# MDR32F21QI register map
Vendor: Milandr; File version: 1.0
CPU: CM0 r0p0, little endian, no MPU, no FPU, 2 interrupt priority bits
Registers are 32-bit, read-write, reset 0x0 unless marked. A register's access mark holds for its fields unless they carry their own. Offsets are from the block's base; [hi:lo] are bit positions; {n}, {i} and the like mark numbered series; 'fields as' and 'values as' point back to an identical list.

## MDR_ADCUI — Energy Counter Block
Base 0x40068000
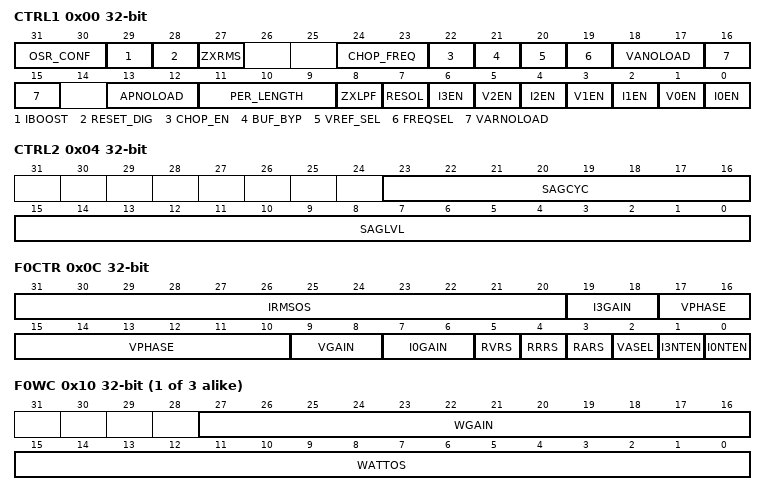
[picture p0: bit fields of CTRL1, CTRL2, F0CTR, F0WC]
0x00 CTRL1 (reset mask 0xF83FBFC3) — ADCUI Control1 Register
  [31:30] OSR_CONF — ADC Output Sampling Rate
    0=4kHz (Sampling at 4kHz); 1=8kHz (Sampling at 8kHz); 2=16kHz (Sampling at 16kHz)
  [29] IBOOST — Boost ADCUI current
  [28] RESET_DIG — Digital Logic Reset
  [27] ZXRMS — RMS Update mode
    0=Continuous RMS update; 1=OnCrossZeroV0 (Update on V0 cross zero level)
  [24:23] CHOP_FREQ — Chopper Frequency
    0=fADC_div2 (ADC freq div 2); 1=fADC_div4 (ADC freq div 4); 2=fADC_div8 (ADC freq div 8); 3=fADC_div16 (ADC freq div 16)
  [22] CHOP_EN — Chopper Mode Select
  [21] BUF_BYP — Bypass Vref buffer
  [20] VREF_SEL
    0=Internal Vref source; 1=External Vref source
  [19] FREQSEL — Enable V0 period detection to FxMD0.PER_FREQ
    0=Off (Hold Last value); 1=On (Enabled)
  [18:17] VANOLOAD — No load mode when calculating full energy
    0=All (Accumulate All Energy); 1=Ignore_Less_1p2basis (Ignore Energy less than 0.012% of full scale); 2=Ignore_Less_0p61basis (Ignore Energy less than 0.0061% of full scale); 3=Ignore_Less_0p305basis (Ignore Energy less than 0.00305% of full scale)
  [16:15] VARNOLOAD — No load mode when calculating reactive energy
    values as VANOLOAD
  [13:12] APNOLOAD — No load mode when calculating active energy
    values as VANOLOAD
  [11:9] PER_LENGTH — Period to calc aver period and dPhase
    0=Period_1 (1 period); 1=Period_2 (2 periods); 2=Period_4 (4 periods); 3=Period_8 (8 periods); 4=Period_16 (16 periods); 5=Period_32 (32 periods); 6=Period_64 (64 periods); 7=Period_128 (128 periods)
  [8] ZXLPF — V0 cross zero LPF enable
  [7] RESOL — Data resolution
    0=16 bit data; 1=24 bit data
  [2n] I{n}EN (n=0..3) — I{n} channel enable
  [5] V2EN — V2 channel enable
  [3] V1EN — V1 channel enable
  [1] V0EN — V0 channel enable
0x04 CTRL2 — ADCUI Control2 Register
  [23:16] SAGCYC — Number of voltage half periods to calc voltage drop level
  [15:0] SAGLVL — The level of permitted voltage drop
0x08 CTRL3 — ADCUI Control3 Register
  [11:0] ZTXOUT — Voltage cross zero timeout
0x0C F0CTR
  [31:20] IRMSOS — RMS calibration of channel I
  [19:18] I3GAIN — PGA value
    0=Signal amplification 0dB; 1=x2 (Signal amplification 6dB); 2=x4 (Signal amplification 12dB); 3=x8 (Signal amplification 18dB)
  [17:10] VPHASE — Phase V0 adjustment by step of +-124us
  [9:8] VGAIN — PGA value
    values as I3GAIN
  [7:6] I0GAIN — PGA value
    values as I3GAIN
  [5] RVRS wo — Full Energy Accumulator Reset
  [4] RRRS wo — Reactive Energy Accumulator Reset
  [3] RARS wo — Active Energy Accumulator Reset
  [2] VASEL — Select source for FullEnergy
    0=FullEnergy (I0DAT and VDAT can store FullEnergy); 1=I_RMS (I0DAT and VDAT can store I_RMS)
  [1] I3NTEN — I3 integrator enable
  [0] I0NTEN — I0 integrator enable
{0x10+0x58*i} F{i}WC (i=0..2) — Active energy calibration
  [27:16] WGAIN — Calibration gain of active energy
  [15:0] WATTOS — Calibration bias of active energy
{0x14+0x58*i} F{i}WATTP ro (i=0..2) — Positive Active Energy accumulator
  [31:0] WATTHRP — High 32 bits of 57-bits Accumulator
{0x18+0x58*i} F{i}WATTN ro (i=0..2) — Negative Active Energy accumulator
  [31:0] WATTHRN — High 32 bits of 57-bits Accumulator
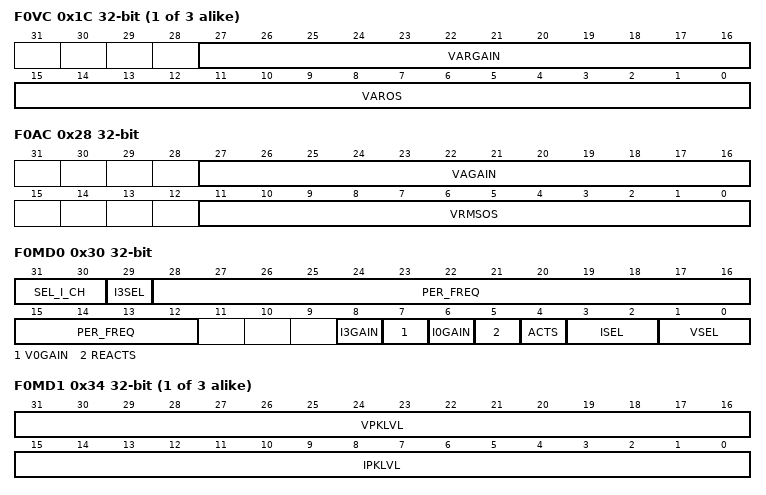
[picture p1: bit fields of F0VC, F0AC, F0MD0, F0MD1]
{0x1C+0x58*i} F{i}VC (i=0..2) — Reactive energy calibration
  [27:16] VARGAIN — Calibration gain of reactive energy
  [15:0] VAROS — Calibration bias of reactive energy
{0x20+0x58*i} F{i}VARP ro (i=0..2) — Positive Reactive Energy accumulator
  [31:0] VARHRP — High 32 bits of of 57-bits Accumulator
{0x24+0x58*i} F{i}VARN ro (i=0..2) — Negative Reactive Energy accumulator
  [31:0] VARHRN — High 32 bits of of 57-bits Accumulator
0x28 F0AC — V0 RMS calibration
  [27:16] VAGAIN — Calibration gain of Full energy
  [11:0] VRMSOS — Calibration bias of V RMS
{0x2C+0x58*i} F{i}VR ro (i=0..2) — Full Energy accumulator
  [31:0] VAHR — High 32 bits of of 57-bits Accumulator
0x30 F0MD0 — FxMD0 register
  [31:30] SEL_I_CH — Select I for calc power
    0=Auto_max (Select max of I0 and I3); 1=I0 (Calc Power by I0); 2=I3 (Calc Power by I3)
  [29] I3SEL — Select source for FxI3DAT
    0=AfterLPF (Signal after LPF); 1=BeforeLPF (ADC_I3 output)
  [28:12] PER_FREQ ro — Measured period in Voltage channel
  [8] I3GAIN — ADC Decimation gain
    0=No gain; 1=x2 (Gain by +6dB)
  [7] V0GAIN — ADC Decimation gain
    0=No gain; 1=x2 (Gain by +6dB)
  [6] I0GAIN — ADC Decimation gain
    0=No gain; 1=x2 (Gain by +6dB)
  [5] REACTS ro — Reactive Energy sign in last period
    0=Pos (Positive sign); 1=Neg (Negative sign)
  [4] ACTS ro — Active Energy sign in last period
    0=Pos (Positive sign); 1=Neg (Negative sign)
  [3:2] ISEL — Select source for FxI0DAT
    0=ADC_I0 (ADC_I0 output); 1=ActivePower; 2=ReactivePower; 3=FullPower
  [1:0] VSEL — Select source for FxVDAT
    0=ADC_V (ADC_V output); 1=ActivePower; 2=ReactivePower; 3=FullPower
{0x34+0x58*i} F{i}MD1 (reset mask 0xFFFFFF) (i=0..2) — FxMD1 register
  [31:16] VPKLVL — Vmax level
  [15:0] IPKLVL — Imax level
0x38 F0VPEAK — VPEAK Result register
  [23:0] IPEAK — Vmax measured, write any to clear
0x3C F0IPEAK — IPEAK Result register
  [23:0] IPEAK — Imax measured, write any to clear
0x40 F0VDAT ro — VDAT Result register
  [23:0] VDAT — FIFO of V or Power
0x44 F0I0DAT ro — I0DAT Result register
  [23:0] IDAT — FIFO of I or Power
0x48 F0I3DAT ro — I3DAT Result register
  [23:0] I3DAT — FIFO of I3 or Power
{0x4C+0x58*i} F{i}VRMS ro (i=0..2) — VRMS Result register
  [23:0] VRMS — RMS of V
{0x50+0x58*i} F{i}VRMS2 ro (i=0..2) — VRMS^2 Result register
  [23:0] VRMS2 — RMS of V^2
{0x54+0x58*i} F{i}IRMS ro (i=0..2) — IRMS Result register
  [23:0] IRMS — RMS of I
{0x58+0x58*i} F{i}IRMS2 ro (i=0..2) — IRMS^2 Result register
  [23:0] IRMS2 — RMS of I^2
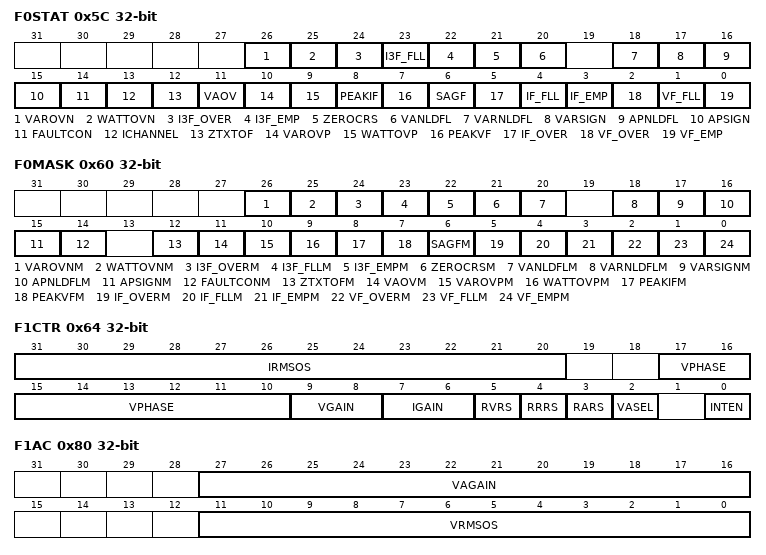
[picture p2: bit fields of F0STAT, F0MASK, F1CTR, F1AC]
0x5C F0STAT — Status Register
  [26] VAROVN — FxVARN value overflow
  [25] WATTOVN — FxWATTN value overflow
  [24] I3F_OVER — FIFO_I3DAT is Overflow
  [23] I3F_FLL ro — FIFO_I3DAT is Full
  [22] I3F_EMP ro — FIFO_I3DAT is Empty
  [21] ZEROCRS — V crossed zero
  [20] VANLDFL ro — FullPower less CNTL1.VANOLOAD
  [18] VARNLDFL ro — ReactivePower less CNTL1.VARNOLOAD
  [17] VARSIGN — ReactivePower sign changed
  [16] APNLDFL ro — ActivePower less CNTL1.APNOLOAD
  [15] APSIGN — ActivePower sign changed
  [14] FAULTCON — Active I switched
  [13] ICHANNEL ro — Timeout of V cross zero
    0=I0 (I0 is active); 1=I3 (I3 is active)
  [12] ZTXTOF — Timeout of V cross zero
  [11] VAOV — FxVR value overflow
  [10] VAROVP — FxVARP value overflow
  [9] WATTOVP — FxWATTP value overflow
  [8] PEAKIF — I exceeds F0MD1.VPKLVL
  [7] PEAKVF — V exceeds F0MD1.VPKLVL
  [6] SAGF — V is less than CTRL2.SAGLVL
  [5] IF_OVER — FIFO_IDAT is Overflow
  [4] IF_FLL ro — FIFO_IDAT is Full
  [3] IF_EMP ro — FIFO_IDAT is Empty
  [2] VF_OVER — FIFO_VDAT is Overflow
  [1] VF_FLL ro — FIFO_VDAT is Full
  [0] VF_EMP ro — FIFO_VDAT is Empty
0x60 F0MASK — IRQ Mask Register
  [26] VAROVNM — FxVARN value overflow
  [25] WATTOVNM — FxWATTN value overflow
  [24] I3F_OVERM — FIFO_I3DAT is Overflow
  [23] I3F_FLLM — FIFO_I3DAT is Full
  [22] I3F_EMPM — FIFO_I3DAT is Empty
  [21] ZEROCRSM — V crossed zero
  [20] VANLDFLM — FullPower less CNTL1.VANOLOAD
  [18] VARNLDFLM — ReactivePower less CNTL1.VARNOLOAD
  [17] VARSIGNM — ReactivePower sign changed
  [16] APNLDFLM — ActivePower less CNTL1.APNOLOAD
  [15] APSIGNM — ActivePower sign changed
  [14] FAULTCONM — Active I switched
  [12] ZTXTOFM — Timeout of V cross zero
  [11] VAOVM — FxVR value overflow
  [10] VAROVPM — FxVARP value overflow
  [9] WATTOVPM — FxWATTP value overflow
  [8] PEAKIFM — I exceeds F0MD1.VPKLVL
  [7] PEAKVFM — V exceeds F0MD1.VPKLVL
  [6] SAGFM — V is less than CTRL2.SAGLVL
  [5] IF_OVERM — FIFO_IDAT is Overflow
  [4] IF_FLLM — FIFO_IDAT is Full
  [3] IF_EMPM — FIFO_IDAT is Empty
  [2] VF_OVERM — FIFO_VDAT is Overflow
  [1] VF_FLLM — FIFO_VDAT is Full
  [0] VF_EMPM — FIFO_VDAT is Empty
0x64 F1CTR — FxCTR register
  [31:20] IRMSOS — RMS calibration of channel I
  [17:10] VPHASE — Phase V adjustment by step of +-124us
  [9:8] VGAIN — PGA value
    values as F0CTR.I3GAIN
  [7:6] IGAIN — PGA value
    values as F0CTR.I3GAIN
  [5] RVRS wo — Full Energy Accumulator Reset
  [4] RRRS wo — Reactive Energy Accumulator Reset
  [3] RARS wo — Active Energy Accumulator Reset
  [2] VASEL — Select source for FullEnergy
    0=FullEnergy (IDAT and VDAT can store FullEnergy); 1=I_RMS (IDAT and VDAT can store I_RMS)
  [0] INTEN — Integrator enable
0x80 F1AC — V RMS calibration
  fields as F0AC
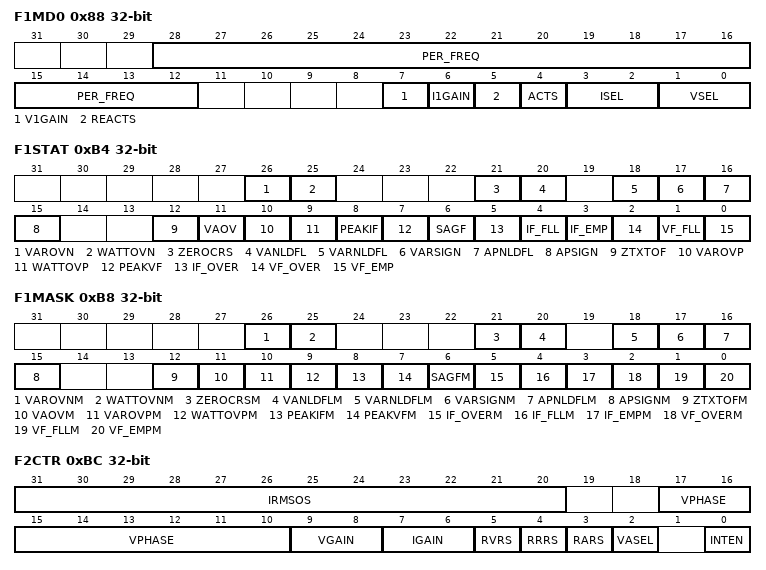
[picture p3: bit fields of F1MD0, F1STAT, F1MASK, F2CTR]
0x88 F1MD0 — FxMD0 register
  [28:12] PER_FREQ ro — Measured period in Voltage channel
  [7] V1GAIN — ADC Decimation gain
    0=No gain; 1=x2 (Gain by +6dB)
  [6] I1GAIN — ADC Decimation gain
    0=No gain; 1=x2 (Gain by +6dB)
  [5] REACTS ro — Reactive Energy sign in last period
    0=Pos (Positive sign); 1=Neg (Negative sign)
  [4] ACTS ro — Active Energy sign in last period
    0=Pos (Positive sign); 1=Neg (Negative sign)
  [3:2] ISEL — Select source for FxI0DAT
    values as F0MD0.ISEL
  [1:0] VSEL — Select source for FxVDAT
    values as F0MD0.VSEL
0x90 F1MD2 ro — FxMD2 register
  [16:0] PhaseV_toV0 — Phase V1 ref to V0
0x94 F1VPEAK — VPEAK Result register
  [23:0] IPEAK — Vmax measured, write any to clear
0x98 F1IPEAK — IPEAK Result register
  [23:0] IPEAK — Imax measured, write any to clear
0x9C F1VDAT ro — VDAT Result register
  [23:0] VDAT — FIFO of V or Power
0xA0 F1IDAT ro — I1DAT Result register
  [23:0] IDAT — FIFO of I or Power
0xB4 F1STAT — Status Register
  [26] VAROVN — FxVARN value overflow
  [25] WATTOVN — FxWATTN value overflow
  [21] ZEROCRS — V crossed zero
  [20] VANLDFL ro — FullPower less CNTL1.VANOLOAD
  [18] VARNLDFL ro — ReactivePower less CNTL1.VARNOLOAD
  [17] VARSIGN — ReactivePower sign changed
  [16] APNLDFL ro — ActivePower less CNTL1.APNOLOAD
  [15] APSIGN — ActivePower sign changed
  [12] ZTXTOF — Timeout of V cross zero
  [11] VAOV — FxVR value overflow
  [10] VAROVP — FxVARP value overflow
  [9] WATTOVP — FxWATTP value overflow
  [8] PEAKIF — I exceeds F0MD1.VPKLVL
  [7] PEAKVF — V exceeds F0MD1.VPKLVL
  [6] SAGF — V is less than CTRL2.SAGLVL
  [5] IF_OVER — FIFO_IDAT is Overflow
  [4] IF_FLL ro — FIFO_IDAT is Full
  [3] IF_EMP ro — FIFO_IDAT is Empty
  [2] VF_OVER — FIFO_VDAT is Overflow
  [1] VF_FLL ro — FIFO_VDAT is Full
  [0] VF_EMP ro — FIFO_VDAT is Empty
0xB8 F1MASK — IRQ Mask Register
  [26] VAROVNM — FxVARN value overflow
  [25] WATTOVNM — FxWATTN value overflow
  [21] ZEROCRSM — V crossed zero
  [20] VANLDFLM — FullPower less CNTL1.VANOLOAD
  [18] VARNLDFLM — ReactivePower less CNTL1.VARNOLOAD
  [17] VARSIGNM — ReactivePower sign changed
  [16] APNLDFLM — ActivePower less CNTL1.APNOLOAD
  [15] APSIGNM — ActivePower sign changed
  [12] ZTXTOFM — Timeout of V cross zero
  [11] VAOVM — FxVR value overflow
  [10] VAROVPM — FxVARP value overflow
  [9] WATTOVPM — FxWATTP value overflow
  [8] PEAKIFM — I exceeds F0MD1.VPKLVL
  [7] PEAKVFM — V exceeds F0MD1.VPKLVL
  [6] SAGFM — V is less than CTRL2.SAGLVL
  [5] IF_OVERM — FIFO_IDAT is Overflow
  [4] IF_FLLM — FIFO_IDAT is Full
  [3] IF_EMPM — FIFO_IDAT is Empty
  [2] VF_OVERM — FIFO_VDAT is Overflow
  [1] VF_FLLM — FIFO_VDAT is Full
  [0] VF_EMPM — FIFO_VDAT is Empty
0xBC F2CTR — FxCTR register
  fields as F1CTR
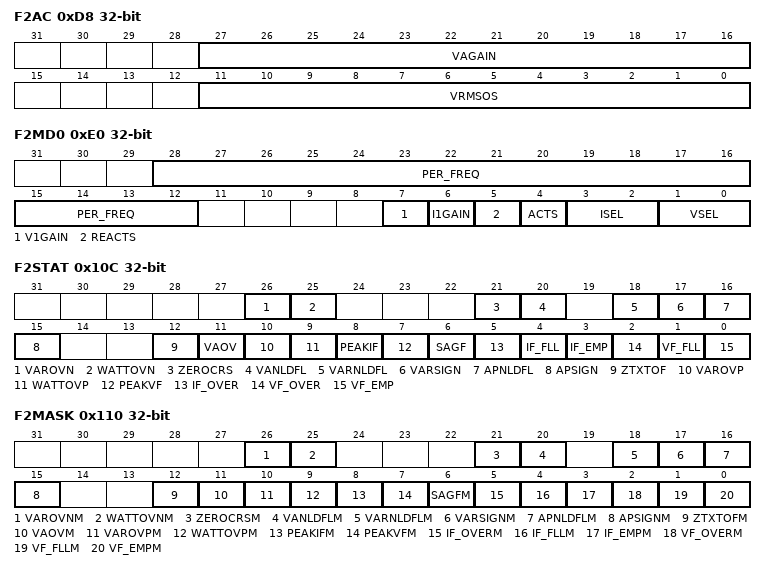
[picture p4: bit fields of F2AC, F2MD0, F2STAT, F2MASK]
0xD8 F2AC — V RMS calibration
  fields as F0AC
0xE0 F2MD0 — FxMD0 register
  fields as F1MD0
0xE8 F2MD2 ro — FxMD2 register
  [16:0] PhaseV_toV0 — Phase V2 ref to V0
0xEC F2VPEAK — VPEAK Result register
  [23:0] IPEAK — Vmax measured, write any to clear
0xF0 F2IPEAK — IPEAK Result register
  [23:0] IPEAK — Imax measured, write any to clear
0xF4 F2VDAT ro — VDAT Result register
  [23:0] VDAT — FIFO of V or Power
0xF8 F2IDAT ro — IDAT Result register
  [23:0] IDAT — FIFO of I or Power
0x10C F2STAT — Status Register
  fields as F1STAT
0x110 F2MASK — IRQ Mask Register
  fields as F1MASK
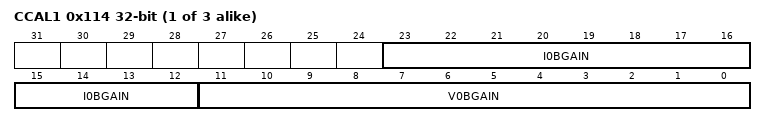
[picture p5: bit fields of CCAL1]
{0x110+4i} CCAL{i} (i=1..3) — Calibration Register {i}
  [23:12] I{i-1}BGAIN — I{i-1} calibration gain
  [11:0] V{i-1}BGAIN — V{i-1} calibration gain
0x120 CCAL4 — Calibration Register 4
  [11:0] I3BGAIN — I3 calibration gain
